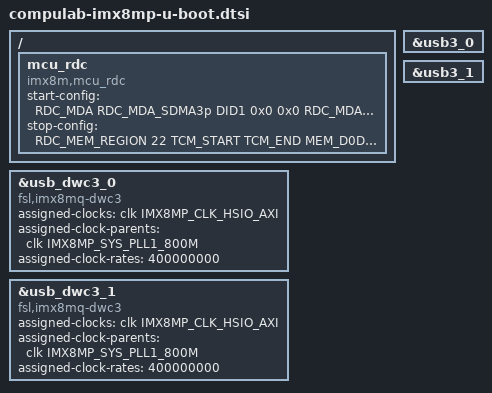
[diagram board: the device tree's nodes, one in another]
#include "imx8mp-sec-def.h"

/ {
	mcu_rdc {
		compatible = "imx8m,mcu_rdc";
			    /* rdc config when MCU starts
			     * master
			     *   SDMA3p --> domain 1
			     *   SDMA3b --> domian 1
			     *   SDMA3_SPBA2  --> domian 1
			     * peripheral:
			     *   SAI3   --> Only Domian 1 can access
			     *   UART4  --> Only Domian 1 can access
			     *   GPT1   --> Only Domian 1 can access
			     *   SDMA3  --> Only Domian 1 can access
			     *   I2C3   --> Only Domian 1 can access
			     * memory:
			     *   TCM    --> Only Domian 1 can access (0x7E0000~0x81FFFF)
			     *   DDR    --> Only Domian 1 can access (0x80000000~0x81000000)
			     * end.
			     */
		start-config = <
			    RDC_MDA  RDC_MDA_SDMA3p DID1 0x0 0x0
			    RDC_MDA  RDC_MDA_ENET1_TX DID1 0x0 0x0
			    RDC_MDA  RDC_MDA_ENET1_RX DID1 0x0 0x0
			    RDC_MDA  RDC_MDA_SDMA3b DID1 0x0 0x0
			    RDC_MDA  RDC_MDA_SDMA3_SPBA2 DID1 0x0 0x0
			    RDC_PDAP RDC_PDAP_ENET1 PDAP_D0D1_ACCESS 0x0 0x0
			    RDC_PDAP RDC_PDAP_SAI3  PDAP_D1_ACCESS 0x0 0x0
			    RDC_PDAP RDC_PDAP_UART4 PDAP_D1_ACCESS 0x0 0x0
			    RDC_PDAP RDC_PDAP_GPT1  PDAP_D1_ACCESS 0x0 0x0
			    RDC_PDAP RDC_PDAP_SDMA3 PDAP_D1_ACCESS 0x0 0x0
			    RDC_PDAP RDC_PDAP_I2C3  PDAP_D1_ACCESS 0x0 0x0
			    RDC_MEM_REGION 22 TCM_START TCM_END MEM_D1_ACCESS
			    RDC_MEM_REGION 39 M4_DDR_START M4_DDR_END MEM_D1_ACCESS
			    0x0      0x0            0x0  0x0 0x0
			  >;
			    /* rdc config when MCU stops
			     * memory:
			     *   TCM    --> domain 0/1 can access (0x7E0000~0x81FFFF)
			     *   DDR    --> domain 0/1 can access (0x80000000~0x81000000)
			     * end.
			     */
		stop-config = <
			    RDC_MEM_REGION 22 TCM_START TCM_END MEM_D0D1_ACCESS
			    RDC_MEM_REGION 39 M4_DDR_START M4_DDR_END MEM_D0D1_ACCESS
			    0x0      0x0            0x0  0x0 0x0
			  >;
	};
};

&usb3_0 {
	u-boot,dm-spl;
	status = "okay";
};

&usb3_1 {
	u-boot,dm-spl;
	status = "okay";
};

&usb_dwc3_0 {
	u-boot,dm-spl;
	compatible = "fsl,imx8mq-dwc3", "snps,dwc3";
	assigned-clocks = <&clk IMX8MP_CLK_HSIO_AXI>;
	assigned-clock-parents = <&clk IMX8MP_SYS_PLL1_800M>;
	assigned-clock-rates = <400000000>;
	status = "okay";
};

&usb_dwc3_1 {
	u-boot,dm-spl;
	compatible = "fsl,imx8mq-dwc3", "snps,dwc3";
	assigned-clocks = <&clk IMX8MP_CLK_HSIO_AXI>;
	assigned-clock-parents = <&clk IMX8MP_SYS_PLL1_800M>;
	assigned-clock-rates = <400000000>;
	status = "okay";
};

